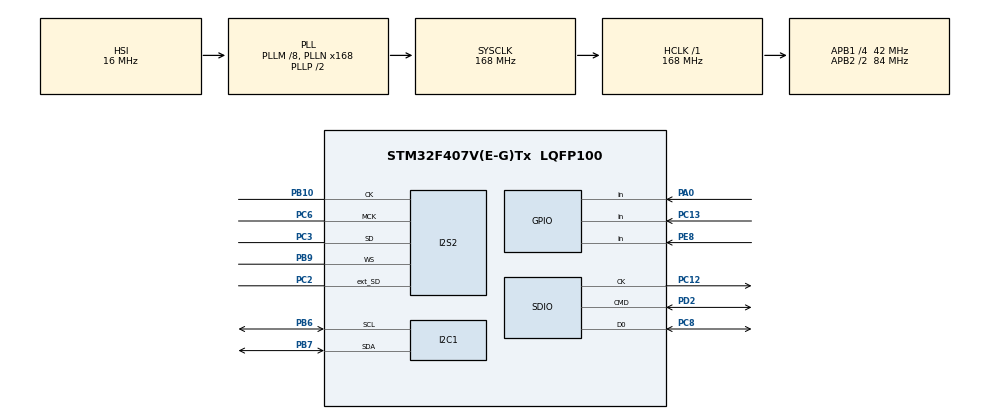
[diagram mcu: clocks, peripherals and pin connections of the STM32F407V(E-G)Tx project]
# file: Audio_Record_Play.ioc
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Dma.I2S2_EXT_RX.0.Direction=DMA_PERIPH_TO_MEMORY
Dma.I2S2_EXT_RX.0.FIFOMode=DMA_FIFOMODE_DISABLE
Dma.I2S2_EXT_RX.0.Instance=DMA1_Stream3
Dma.I2S2_EXT_RX.0.MemDataAlignment=DMA_MDATAALIGN_HALFWORD
Dma.I2S2_EXT_RX.0.MemInc=DMA_MINC_ENABLE
Dma.I2S2_EXT_RX.0.Mode=DMA_CIRCULAR
Dma.I2S2_EXT_RX.0.PeriphDataAlignment=DMA_PDATAALIGN_HALFWORD
Dma.I2S2_EXT_RX.0.PeriphInc=DMA_PINC_DISABLE
Dma.I2S2_EXT_RX.0.Priority=DMA_PRIORITY_VERY_HIGH
Dma.Request0=I2S2_EXT_RX
Dma.Request1=SPI2_TX
Dma.SPI2_TX.1.Direction=DMA_MEMORY_TO_PERIPH
Dma.SPI2_TX.1.FIFOMode=DMA_FIFOMODE_DISABLE
Dma.SPI2_TX.1.Instance=DMA1_Stream4
Dma.SPI2_TX.1.MemDataAlignment=DMA_MDATAALIGN_HALFWORD
Dma.SPI2_TX.1.MemInc=DMA_MINC_ENABLE
Dma.SPI2_TX.1.Mode=DMA_CIRCULAR
Dma.SPI2_TX.1.PeriphDataAlignment=DMA_PDATAALIGN_HALFWORD
Dma.SPI2_TX.1.PeriphInc=DMA_PINC_DISABLE
Dma.SPI2_TX.1.Priority=DMA_PRIORITY_VERY_HIGH
I2S2.AudioFreq=I2S_AUDIOFREQ_16K
I2S2.ErrorAudioFreq=1.72 %
I2S2.FullDuplexMode=I2S_FULLDUPLEXMODE_ENABLE
I2S2.Instance=SPI$Index
I2S2.RealAudioFreq=16.276 KHz
I2S2.VirtualMode=I2S_MODE_MASTER
Mcu.Family=STM32F4
Mcu.Name=STM32F407V(E-G)Tx
Mcu.Package=LQFP100
NVIC.DMA1_Stream3_IRQn=true\:0\:0\:false\:false\:true\:false\:true\:true
NVIC.DMA1_Stream4_IRQn=true\:0\:0\:false\:false\:true\:false\:true\:true
NVIC.PriorityGroup=NVIC_PRIORITYGROUP_4
NVIC.SDIO_IRQn=true\:0\:0\:false\:false\:true\:true\:true\:true
PA0-WKUP.GPIO_PuPd=GPIO_PULLUP
PA0-WKUP.Signal=GPIO_Input
PB10.GPIO_PuPd=GPIO_NOPULL
PB10.GPIO_Speed=GPIO_SPEED_FREQ_VERY_HIGH
PB10.Mode=Full_Duplex_Master
PB10.Signal=I2S2_CK
PB6.GPIO_Pu=GPIO_PULLUP
PB6.GPIO_Speed=GPIO_SPEED_FREQ_HIGH
PB6.Mode=I2C
PB6.Signal=I2C1_SCL
PB7.GPIO_Pu=GPIO_PULLUP
PB7.GPIO_Speed=GPIO_SPEED_FREQ_HIGH
PB7.Mode=I2C
PB7.Signal=I2C1_SDA
PB9.GPIO_PuPd=GPIO_NOPULL
PB9.GPIO_Speed=GPIO_SPEED_FREQ_VERY_HIGH
PB9.Mode=Full_Duplex_Master
PB9.Signal=I2S2_WS
PC12.GPIO_PuPd=GPIO_PULLUP
PC12.Mode=SD_1_bit
PC12.Signal=SDIO_CK
PC13-ANTI_TAMP.GPIO_PuPd=GPIO_PULLUP
PC13-ANTI_TAMP.Signal=GPIO_Input
PC2.GPIO_PuPd=GPIO_NOPULL
PC2.GPIO_Speed=GPIO_SPEED_FREQ_VERY_HIGH
PC2.Mode=Full_Duplex_Master
PC2.Signal=I2S2_ext_SD
PC3.GPIO_PuPd=GPIO_NOPULL
PC3.GPIO_Speed=GPIO_SPEED_FREQ_VERY_HIGH
PC3.Mode=Full_Duplex_Master
PC3.Signal=I2S2_SD
PC6.GPIO_PuPd=GPIO_NOPULL
PC6.GPIO_Speed=GPIO_SPEED_FREQ_VERY_HIGH
PC6.Mode=Master_Clock_Activated
PC6.Signal=I2S2_MCK
PC8.GPIO_PuPd=GPIO_PULLUP
PC8.Mode=SD_1_bit
PC8.Signal=SDIO_D0
PD2.GPIO_PuPd=GPIO_PULLUP
PD2.Mode=SD_1_bit
PD2.Signal=SDIO_CMD
PE8.GPIO_PuPd=GPIO_PULLUP
PE8.Signal=GPIO_Input
ProjectManager.HeapSize=0x200
ProjectManager.StackSize=0x400
ProjectManager.TargetToolchain=MDK-ARM V5.32
RCC.48MHZClocksFreq_Value=48000000
RCC.AHBFreq_Value=168000000
RCC.APB1CLKDivider=RCC_HCLK_DIV4
RCC.APB1Freq_Value=42000000
RCC.APB1TimFreq_Value=84000000
RCC.APB2CLKDivider=RCC_HCLK_DIV2
RCC.APB2Freq_Value=84000000
RCC.APB2TimFreq_Value=168000000
RCC.CortexFreq_Value=168000000
RCC.HCLKFreq_Value=168000000
RCC.HSE_VALUE=25000000
RCC.HSI_VALUE=16000000
RCC.LSE_VALUE=32768
RCC.PLLI2SN=50
RCC.PLLM=8
RCC.PLLN=168
RCC.PLLQ=7
RCC.SYSCLKFreq_VALUE=168000000
RCC.SYSCLKSource=RCC_SYSCLKSOURCE_PLLCLK
RCC.VCOOutputFreq_Value=336000000
VP_FATFS_VS_SDIO.Mode=SDIO
board=custom

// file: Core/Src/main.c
/* USER CODE BEGIN Header */
/**
  ******************************************************************************
  * @file           : main.c
  * @brief          : Main program body
  ******************************************************************************
  * @attention
  *
  * Copyright (c) 2026 STMicroelectronics.
  * All rights reserved.
  *
  * This software is licensed under terms that can be found in the LICENSE file
  * in the root directory of this software component.
  * If no LICENSE file comes with this software, it is provided AS-IS.
  *
  ******************************************************************************
  */
/* USER CODE END Header */
#include "main.h"
#include "dma.h"
#include "fatfs.h"
#include "i2c.h"
#include "i2s.h"
#include "sdio.h"
#include "gpio.h"

/* USER CODE BEGIN Includes */
#include "audio_app.h"
#include "oled_ui.h"

/* USER CODE END Includes */

void SystemClock_Config(void);

int main(void)
{

  /* MCU Configuration--------------------------------------------------------*/

  /* Reset of all peripherals, Initializes the Flash interface and the Systick. */
  HAL_Init();

  /* Configure the system clock */
  SystemClock_Config();

  /* Initialize all configured peripherals */
  MX_GPIO_Init();
  MX_DMA_Init();
  MX_I2C1_Init();
  MX_I2S2_Init();
  MX_SDIO_SD_Init();
  MX_FATFS_Init();
  /* USER CODE BEGIN 2 */
  AudioApp_Init();
  OLED_UI_Init();

  /* USER CODE END 2 */

  /* Infinite loop */
  while (1)
  {

    /* USER CODE BEGIN 3 */
    AudioApp_Task();
    OLED_UI_Task();
    HAL_Delay(1);
  }
  /* USER CODE END 3 */
}

void SystemClock_Config(void)
{
  RCC_OscInitTypeDef RCC_OscInitStruct = {0};
  RCC_ClkInitTypeDef RCC_ClkInitStruct = {0};

  /** Configure the main internal regulator output voltage
  */
  __HAL_RCC_PWR_CLK_ENABLE();
  __HAL_PWR_VOLTAGESCALING_CONFIG(PWR_REGULATOR_VOLTAGE_SCALE1);

  /** Initializes the RCC Oscillators according to the specified parameters
  * in the RCC_OscInitTypeDef structure.
  */
  RCC_OscInitStruct.OscillatorType = RCC_OSCILLATORTYPE_HSI;
  RCC_OscInitStruct.HSIState = RCC_HSI_ON;
  RCC_OscInitStruct.HSICalibrationValue = RCC_HSICALIBRATION_DEFAULT;
  RCC_OscInitStruct.PLL.PLLState = RCC_PLL_ON;
  RCC_OscInitStruct.PLL.PLLSource = RCC_PLLSOURCE_HSI;
  RCC_OscInitStruct.PLL.PLLM = 8;
  RCC_OscInitStruct.PLL.PLLN = 168;
  RCC_OscInitStruct.PLL.PLLP = RCC_PLLP_DIV2;
  RCC_OscInitStruct.PLL.PLLQ = 7;
  if (HAL_RCC_OscConfig(&RCC_OscInitStruct) != HAL_OK)
  {
    Error_Handler();
  }

  /** Initializes the CPU, AHB and APB buses clocks
  */
  RCC_ClkInitStruct.ClockType = RCC_CLOCKTYPE_HCLK|RCC_CLOCKTYPE_SYSCLK
                              |RCC_CLOCKTYPE_PCLK1|RCC_CLOCKTYPE_PCLK2;
  RCC_ClkInitStruct.SYSCLKSource = RCC_SYSCLKSOURCE_PLLCLK;
  RCC_ClkInitStruct.AHBCLKDivider = RCC_SYSCLK_DIV1;
  RCC_ClkInitStruct.APB1CLKDivider = RCC_HCLK_DIV4;
  RCC_ClkInitStruct.APB2CLKDivider = RCC_HCLK_DIV2;

  if (HAL_RCC_ClockConfig(&RCC_ClkInitStruct, FLASH_LATENCY_5) != HAL_OK)
  {
    Error_Handler();
  }
}

void Error_Handler(void)
{
  __disable_irq();
  while (1)
  {
  }
}
